# f29h85x_hsm_sec_mgr_regs register map
Vendor: Texas Instruments
Peripheral module from a debugger description file (folder HSM).
Registers are 32-bit, read-write, no defined reset value unless marked. A register's access mark holds for its fields unless they carry their own. Offsets are as the file gives them; lines under a group give offsets from that group; [hi:lo] are bit positions; {n}, {i} and the like mark numbered series; 'fields as' and 'values as' point back to an identical list; <NAME> marks a mode.

## HSM_SEC_MGR — HSM SEC MGR Registers
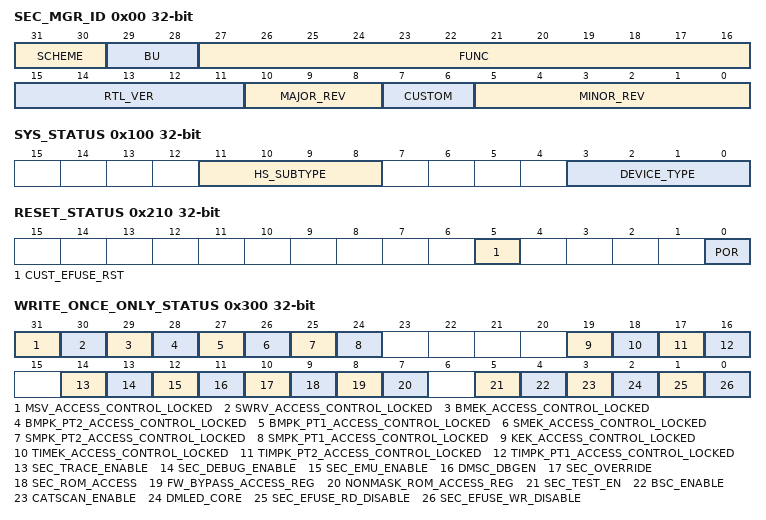
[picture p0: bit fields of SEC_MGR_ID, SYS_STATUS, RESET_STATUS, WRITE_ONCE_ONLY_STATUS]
0x00 SEC_MGR_ID ro — Peripheral ID register
  [31:30] SCHEME, [29:28] BU, [27:16] FUNC, [15:11] RTL_VER, [10:8] MAJOR_REV, [7:6] CUSTOM, [5:0] MINOR_REV
0x100 SYS_STATUS ro — System Status register
  [11:8] HS_SUBTYPE, [3:0] DEVICE_TYPE
0x210 RESET_STATUS ro
  [5] CUST_EFUSE_RST, [0] POR
0x300 WRITE_ONCE_ONLY_STATUS ro
  [31] MSV_ACCESS_CONTROL_LOCKED, [30] SWRV_ACCESS_CONTROL_LOCKED, [29] BMEK_ACCESS_CONTROL_LOCKED, [28] BMPK_PT2_ACCESS_CONTROL_LOCKED, [27] BMPK_PT1_ACCESS_CONTROL_LOCKED, [26] SMEK_ACCESS_CONTROL_LOCKED, [25] SMPK_PT2_ACCESS_CONTROL_LOCKED, [24] SMPK_PT1_ACCESS_CONTROL_LOCKED, [19] KEK_ACCESS_CONTROL_LOCKED, [18] TIMEK_ACCESS_CONTROL_LOCKED, [17] TIMPK_PT2_ACCESS_CONTROL_LOCKED, [16] TIMPK_PT1_ACCESS_CONTROL_LOCKED, [14] SEC_TRACE_ENABLE, [13] SEC_DEBUG_ENABLE, [12] SEC_EMU_ENABLE, [11] DMSC_DBGEN, [10] SEC_OVERRIDE, [9] SEC_ROM_ACCESS, [8] FW_BYPASS_ACCESS_REG, [7] NONMASK_ROM_ACCESS_REG, [5] SEC_TEST_EN, [4] BSC_ENABLE, [3] CATSCAN_ENABLE, [2] DMLED_CORE, [1] SEC_EFUSE_RD_DISABLE, [0] SEC_EFUSE_WR_DISABLE
0x500 EFUSE_JTAG_DISABLE_STATUS ro
  [3:0] JTAG_DISABLE
{0x800+4i} SMPK_PART1_STATUS_REG[{i}] (i=0..7) ro — SMPK-Part1 Reg Status Register
  [31:0] SMPK
{0x850+4i} SMPK_PART2_STATUS_REG[{i}] (i=0..7) ro — SMPK-Part2 Status Register
  [31:0] SMPK
0x880 SMEK_ID_STATUS_REG ro — SMEK ID Status Register
  [31:0] SMEK
{0x900+4i} BMPK_PART1_STATUS_REG[{i}] (i=0..7) ro — BMPK-Part1 Status Register
  [31:0] BMPK
{0x950+4i} BMPK_PART2_STATUS_REG[{i}] (i=0..7) ro — BMPK-Part2 Reg Status Register
  [31:0] BMPK
0x980 BMEK_ID_STATUS_REG ro — BMEK ID Status Register
  [31:0] BMEK
{0xD00+4i} SWRV_STATUS_REG[{i}] (i=0..7) ro — SWRV Status Register
  [31:0] SWRV
0xD50 MSV_STATUS_REG ro — MSV Reg Status Register
  [23:0] MSV
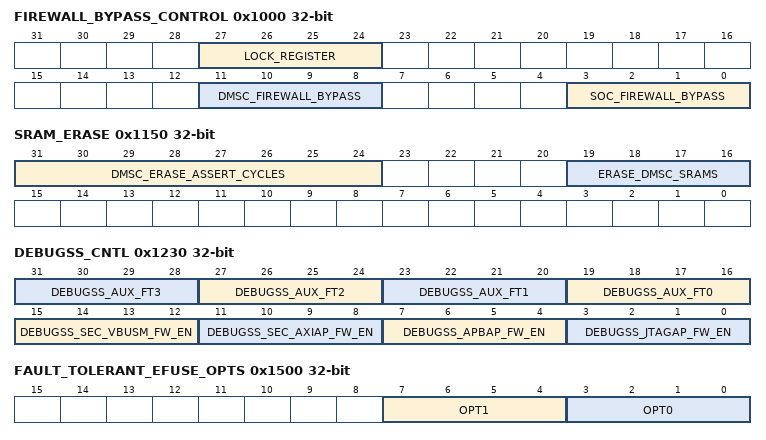
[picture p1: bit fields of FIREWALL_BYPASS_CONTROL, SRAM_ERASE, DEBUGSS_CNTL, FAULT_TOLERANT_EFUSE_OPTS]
0x1000 FIREWALL_BYPASS_CONTROL
  [27:24] LOCK_REGISTER, [11:8] DMSC_FIREWALL_BYPASS, [3:0] SOC_FIREWALL_BYPASS
0x1150 SRAM_ERASE — SRAM Erase and ROM Access Control Register
  [31:24] DMSC_ERASE_ASSERT_CYCLES, [19:16] ERASE_DMSC_SRAMS
0x1200 DMSC_DEBUG_CNTL — DMSC Debug Control Register
  [3:0] DMSC_DBGEN_ENABLE
0x1210 SOC_SEC_DBG_CNTL — SoC Secure Debug/Emulation Control Register
  [3:0] SEC_DBG_ENABLE
0x1220 DEBUGSS_DOM — DebugSS DOM control register
  [10:0] DEBUGSS_SEC_CTL_DOM
0x1230 DEBUGSS_CNTL — DebugSS Control Register
  [4n+19:4n+16] DEBUGSS_AUX_FT{n} (n=0..3), [15:12] DEBUGSS_SEC_VBUSM_FW_EN, [11:8] DEBUGSS_SEC_AXIAP_FW_EN, [7:4] DEBUGSS_APBAP_FW_EN, [3:0] DEBUGSS_JTAGAP_FW_EN
0x1234 DEBUGSS_DBG_TAP_FW_EN — DebugSS Debug Tap Firewall Enable Register
0x1500 FAULT_TOLERANT_EFUSE_OPTS — Fault Tolerant ROM Defined Device Config Efuse Register
  [7:4] OPT1, [3:0] OPT0
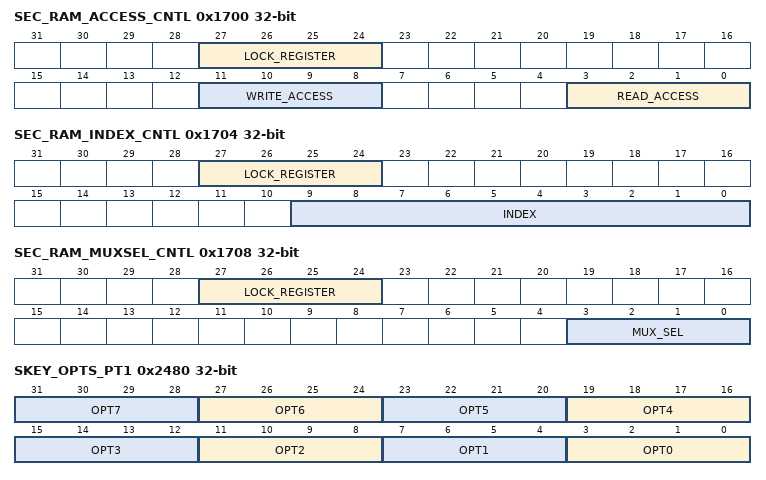
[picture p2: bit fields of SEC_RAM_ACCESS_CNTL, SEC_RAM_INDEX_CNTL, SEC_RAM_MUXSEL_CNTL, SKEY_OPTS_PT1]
0x1700 SEC_RAM_ACCESS_CNTL — External Secure RAM Access Control Register
  [27:24] LOCK_REGISTER, [11:8] WRITE_ACCESS, [3:0] READ_ACCESS
0x1704 SEC_RAM_INDEX_CNTL — External Secure RAM Selection Control Register
  [27:24] LOCK_REGISTER, [9:0] INDEX
0x1708 SEC_RAM_MUXSEL_CNTL — External Secure RAM Selection Control Register
  [27:24] LOCK_REGISTER, [3:0] MUX_SEL
0x1C00 KEK_ACCESS_CNTL access not given — KEK Access Control Register
{0x1C10+4i} SW_KEK_DATA_REG[{i}] (i=0..7) access not given — SW KEK Data Register
0x2000 CUST_KEY_COUNT ro — Customer Key Count Register
  [15:0] CUST_KEY_COUNT
0x2010 CUST_KEY_REV ro — Customer Key Revision Register
  [15:0] CUST_KEY_REVISION
0x2020 CUST_CODE_PROV ro — Customer Code Provisioned Register
  [15:0] CODE_PROVISIONED
0x2030 CUST_FAILURE_ANALYSIS_EN ro — Customer Failure Analysis Enabled Register
  [15:0] EN
0x2040 CUST_DECOMMISSION_EN ro — Decommission Enabled Register
  [15:0] EN
0x2100 CUST_MISC_DATA access not given — Cust Misc Data Access Register
{0x2110+4i} CUST_MISC_DATA_REG[{i}] (i=0..7)
  [31:0] CUST_MISC
0x2200 SMPK_PT1_ACCESS_CNTL access not given — SMPK-Part1 Access Control Register
{0x2210+4i} SMPK_PT1_DATA_REG[{i}] (i=0..7) — SMPK-Part1 Data Register
  [31:0] SMPK
0x2250 SMPK_PT1_BCH — SMPK-Part1 BCH Register
0x2300 SMPK_PT2_ACCESS_CNTL access not given — SMPK-Part2 Access Control Register
{0x2310+4i} SMPK_PT2_DATA_REG[{i}] (i=0..7) — SMPK-Part2 Data Register
  [31:0] SMPK
0x2350 SMPK_PT2_BCH — SMPK-Part2 BCH Register
0x2400 SMEK_ACCESS_CNTL access not given
0x2404 SMEK_ID — SMEK ID Data Register
{0x2410+4i} SMEK_DATA_REG[{i}] (i=0..7) — SMEK Data Register
  [31:0] SMEK
0x2450 SMEK_BCH — SMEK-BCH Key Register
0x2480 SKEY_OPTS_PT1 — Customer SKey Options Part1
  [4n+3:4n] OPT{n} (n=0..7)
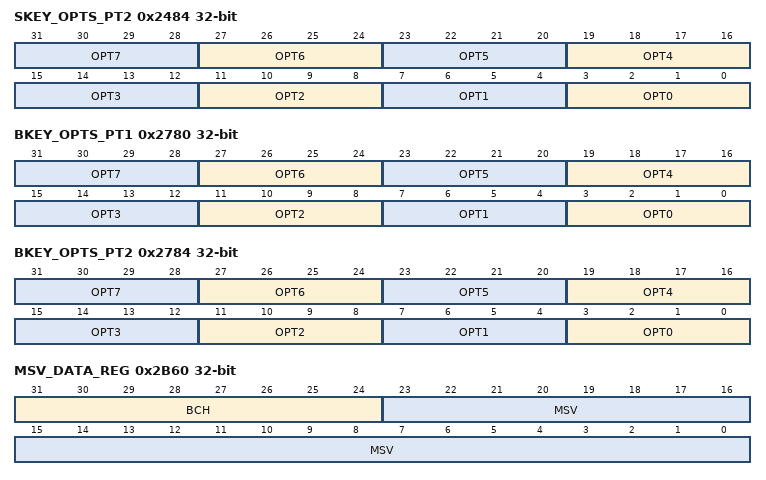
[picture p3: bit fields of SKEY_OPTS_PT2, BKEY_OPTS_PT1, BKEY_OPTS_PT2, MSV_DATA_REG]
0x2484 SKEY_OPTS_PT2 — Customer SKey Options Part2
  [4n+3:4n] OPT{n} (n=0..7)
0x2500 BMPK_PT1_ACCESS_CNTL access not given — BMPK-Part1 Access Control Register
{0x2510+4i} BMPK_PT1_DATA_REG[{i}] (i=0..7) — BMPK-Part1 Data Register
  [31:0] BMPK
0x2550 BMPK_PT1_BCH — BMPK-Part1 BCH Register
0x2600 BMPK_PT2_ACCESS_CNTL access not given — BMPK-Part2 Access Control Register
{0x2610+4i} BMPK_PT2_DATA_REG[{i}] (i=0..7) — BMPK-Part2 Data Register
  [31:0] BMPK
0x2650 BMPK_PT2_BCH — BMPK-Part2 BCH Register
0x2700 BMEK_ACCESS_CNTL access not given
0x2704 BMEK_ID — BMEK ID Data Register
{0x2710+4i} BMEK_DATA_REG[{i}] (i=0..7) — BMEK Data Register
  [31:0] BMEK
0x2750 BMEK_BCH
0x2780 BKEY_OPTS_PT1 — Customer BKey Options Part1
  [4n+3:4n] OPT{n} (n=0..7)
0x2784 BKEY_OPTS_PT2 — Customer BKey Options Part2
  [4n+3:4n] OPT{n} (n=0..7)
0x2B00 SWRV_ACCESS_CNTL access not given — SWRV Access Control Register
{0x2B10+4i} SWRV_DATA_REG[{i}] (i=0..7) — SWRV Data Register
  [31:0] SWRV
0x2B50 MSV_ACCESS_CNTL access not given — MSV Access Control Register
0x2B60 MSV_DATA_REG — MSV Data Register
  [31:24] BCH, [23:0] MSV
{0x2C00+4i} FLASH_WEPROT_REG[{i}] (i=0..3) ro — Flash Wrtie Erase Protection Register
  [31:0] WEPROT
{0x3000+4i} OTP_VAL_REG[{i}] (i=0..51) ro — Customer OTP Viewer Register
  [31:0] OTP_DATA
